# PY32L0xx_DFP register map
Vendor: Puya; Series: PY32L0; File version: 1.0.0
CPU: CM0+ r0p1, little endian, no MPU, no FPU, 4 interrupt priority bits
Registers are 32-bit, read-write, reset 0x0 unless marked. A register's access mark holds for its fields unless they carry their own. Offsets are from the block's base; [hi:lo] are bit positions; {n}, {i} and the like mark numbered series.

## COMP1 — Comparator 1
Base 0x40010200
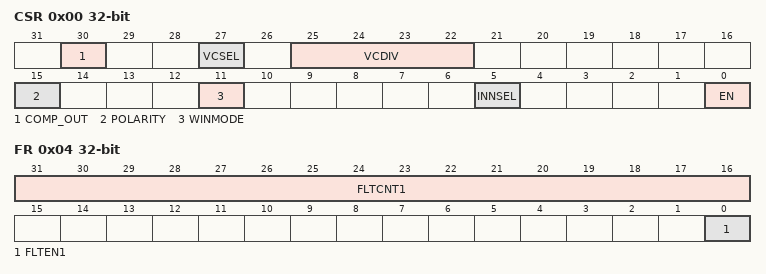
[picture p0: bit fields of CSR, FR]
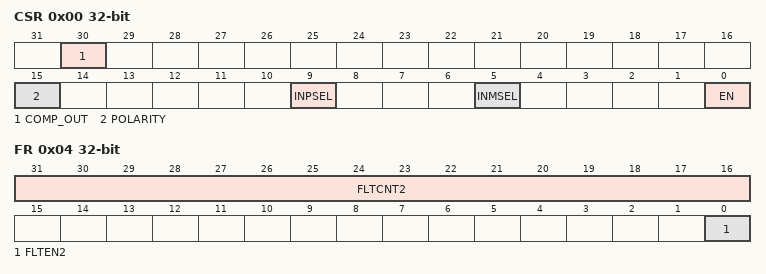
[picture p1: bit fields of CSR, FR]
0x00 CSR — COMP control and status register
  [30] COMP_OUT — Comparator output status
  [27] VCSEL
  [25:22] VCDIV
  [15] POLARITY — Comparator polarity selector
  [11] WINMODE — Comparator non-inverting input selector for window mode
  [5] INNSEL
  [0] EN — COMP enable bit
0x04 FR — Comparator Filter register
  [31:16] FLTCNT1 — Comparator filter and counter
  [0] FLTEN1 — Filter enable bit

## COMP2 — Comparator2
Base 0x40010210
0x00 CSR — COMP control and status register
  [30] COMP_OUT — Comparator output status
  [15] POLARITY — Comparator polarity selector
  [9] INPSEL — Comparator signal selector for non-inverting input
  [5] INMSEL — Comparator signal selector for inverting input INM
  [0] EN — COMP enable bit
0x04 FR — Comparator Filter register
  [31:16] FLTCNT2 — Comparator filter and counter
  [0] FLTEN2 — Filter enable bit

## PWR — Power control
Base 0x40007000
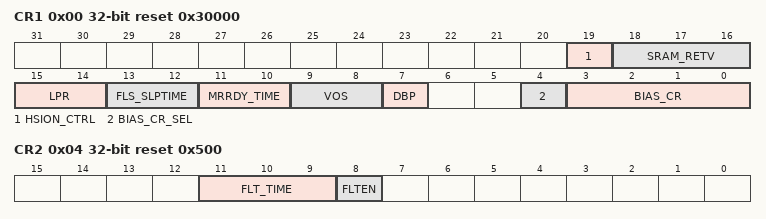
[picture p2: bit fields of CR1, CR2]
0x00 CR1 reset 0x30000 — Power control register 1
  [19] HSION_CTRL — HSI open time control
  [18:16] SRAM_RETV — SRAM retention voltage control
  [15:14] LPR — Low-power run
  [13:12] FLS_SLPTIME — Flash wait time after wakeup from the stop mode
  [11:10] MRRDY_TIME — Time selection wakeup from LP to VR
  [9:8] VOS — Voltage scaling range selection
  [7] DBP — Disable backup domain write protection
  [4] BIAS_CR_SEL — MR Bias current selection
  [3:0] BIAS_CR — MR Bias current
0x04 CR2 reset 0x500 — Power control register 2
  [11:9] FLT_TIME — Digital filter time configuration
  [8] FLTEN — Digital filter enable

## GPIOA — General-purpose I/Os
Base 0x50000000
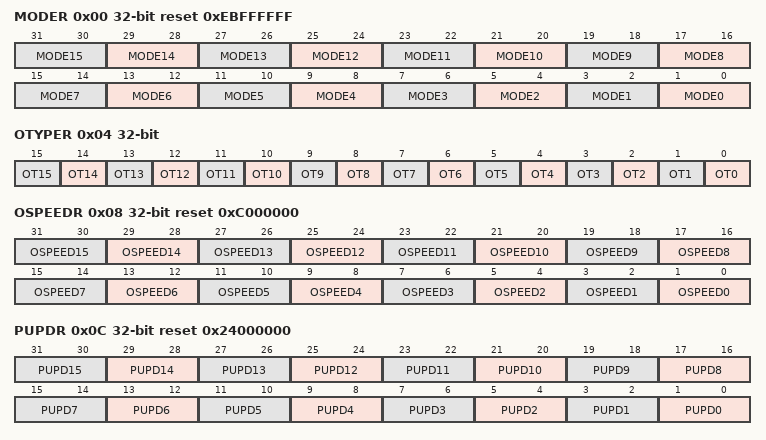
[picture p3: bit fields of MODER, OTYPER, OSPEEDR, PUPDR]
0x00 MODER reset 0xEBFFFFFF — GPIO port mode register
  [2n+1:2n] MODE{n} (n=0..15) — Port x configuration bits (y = 0..15)
0x04 OTYPER — GPIO port output type register
  [n] OT{n} (n=0..15) — Port x configuration bits (y = 0..15)
0x08 OSPEEDR reset 0xC000000 — GPIO port output speed register
  [2n+1:2n] OSPEED{n} (n=0..15) — Port x configuration bits (y = 0..15)
0x0C PUPDR reset 0x24000000 — GPIO port pull-up/pull-down register
  [2n+1:2n] PUPD{n} (n=0..15) — Port x configuration bits (y = 0..15)
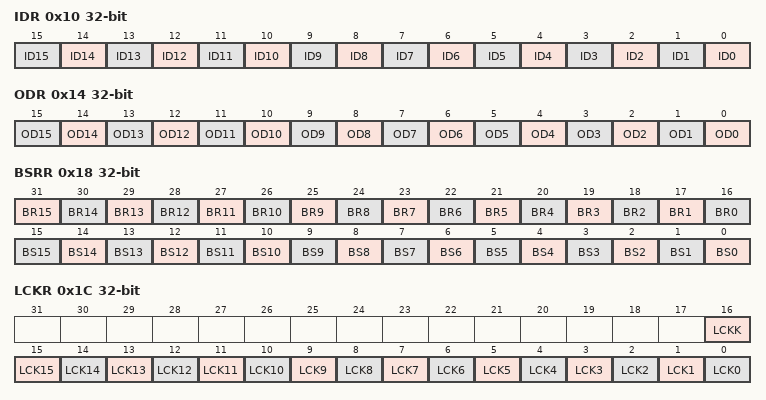
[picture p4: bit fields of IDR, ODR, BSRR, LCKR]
0x10 IDR ro — GPIO port input data register
  [n] ID{n} (n=0..15) — Port input data (y = 0..15)
0x14 ODR — GPIO port output data register
  [n] OD{n} (n=0..15) — Port output data (y = 0..15)
0x18 BSRR wo — GPIO port bit set/reset register
  [n+16] BR{n} (n=1..15) — Port x reset bit y (y = 0..15)
  [16] BR0 — Port x set bit y (y= 0..15)
  [n] BS{n} (n=0..15) — Port x set bit y (y= 0..15)
0x1C LCKR — GPIO port configuration lock register
  [16] LCKK — Port x lock bit y (y= 0..15)
  [n] LCK{n} (n=0..15) — Port x lock bit y (y= 0..15)
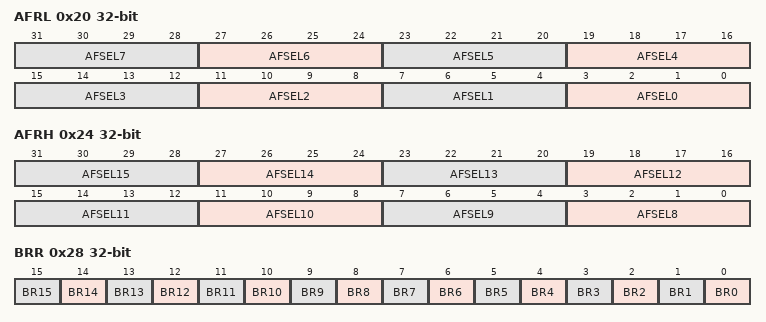
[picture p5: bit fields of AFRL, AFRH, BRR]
0x20 AFRL — GPIO alternate function low register
  [4n+3:4n] AFSEL{n} (n=0..7) — Alternate function selection for port x bit y (y = 0..7)
0x24 AFRH — GPIO alternate function high register
  [4n-29:4n-32] AFSEL{n} (n=8..15) — Alternate function selection for port x bit y (y = 8..15)
0x28 BRR wo — port bit reset register
  [n] BR{n} (n=0..15) — Port Reset bit

## GPIOB — General-purpose I/Os
Base 0x50000400
Same registers: GPIOC 0x50000800
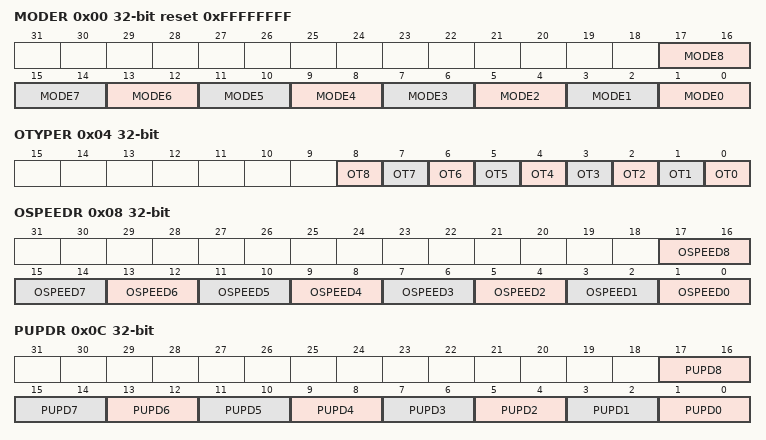
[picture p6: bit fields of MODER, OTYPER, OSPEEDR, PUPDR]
0x00 MODER reset 0xFFFFFFFF — GPIO port mode register
  [2n+1:2n] MODE{n} (n=0..8) — Port x configuration bits (y = 0..15)
0x04 OTYPER — GPIO port output type register
  [n] OT{n} (n=0..8) — Port x configuration bits (y = 0..15)
0x08 OSPEEDR — GPIO port output speed register
  [2n+1:2n] OSPEED{n} (n=0..8) — Port x configuration bits (y = 0..15)
0x0C PUPDR — GPIO port pull-up/pull-down register
  [2n+1:2n] PUPD{n} (n=0..8) — Port x configuration bits (y = 0..15)
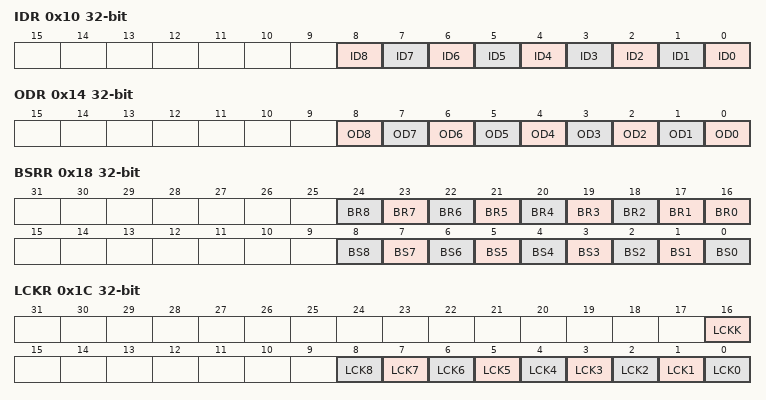
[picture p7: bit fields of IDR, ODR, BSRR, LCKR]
0x10 IDR ro — GPIO port input data register
  [n] ID{n} (n=0..8) — Port input data (y = 0..15)
0x14 ODR — GPIO port output data register
  [n] OD{n} (n=0..8) — Port output data (y = 0..15)
0x18 BSRR wo — GPIO port bit set/reset register
  [n+16] BR{n} (n=1..8) — Port x reset bit y (y = 0..15)
  [16] BR0 — Port x set bit y (y= 0..15)
  [n] BS{n} (n=0..8) — Port x set bit y (y= 0..15)
0x1C LCKR — GPIO port configuration lock register
  [16] LCKK — Port x lock bit y (y= 0..15)
  [n] LCK{n} (n=0..8) — Port x lock bit y (y= 0..15)
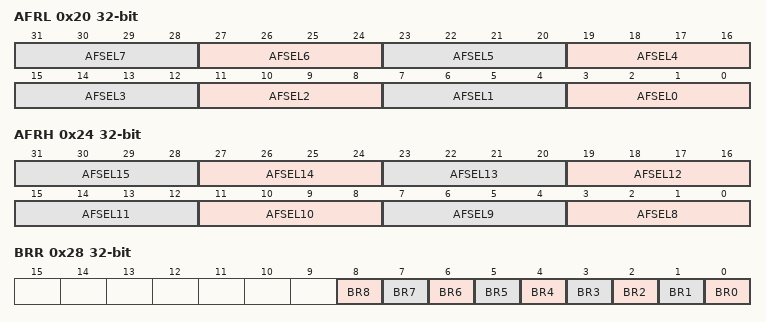
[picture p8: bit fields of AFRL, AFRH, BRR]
0x20 AFRL — GPIO alternate function low register
  [4n+3:4n] AFSEL{n} (n=0..7) — Alternate function selection for port x bit y (y = 0..7)
0x24 AFRH — GPIO alternate function high register
  [4n-29:4n-32] AFSEL{n} (n=8..15) — Alternate function selection for port x bit y (y = 8..15)
0x28 BRR wo — port bit reset register
  [n] BR{n} (n=0..8) — Port Reset bit
